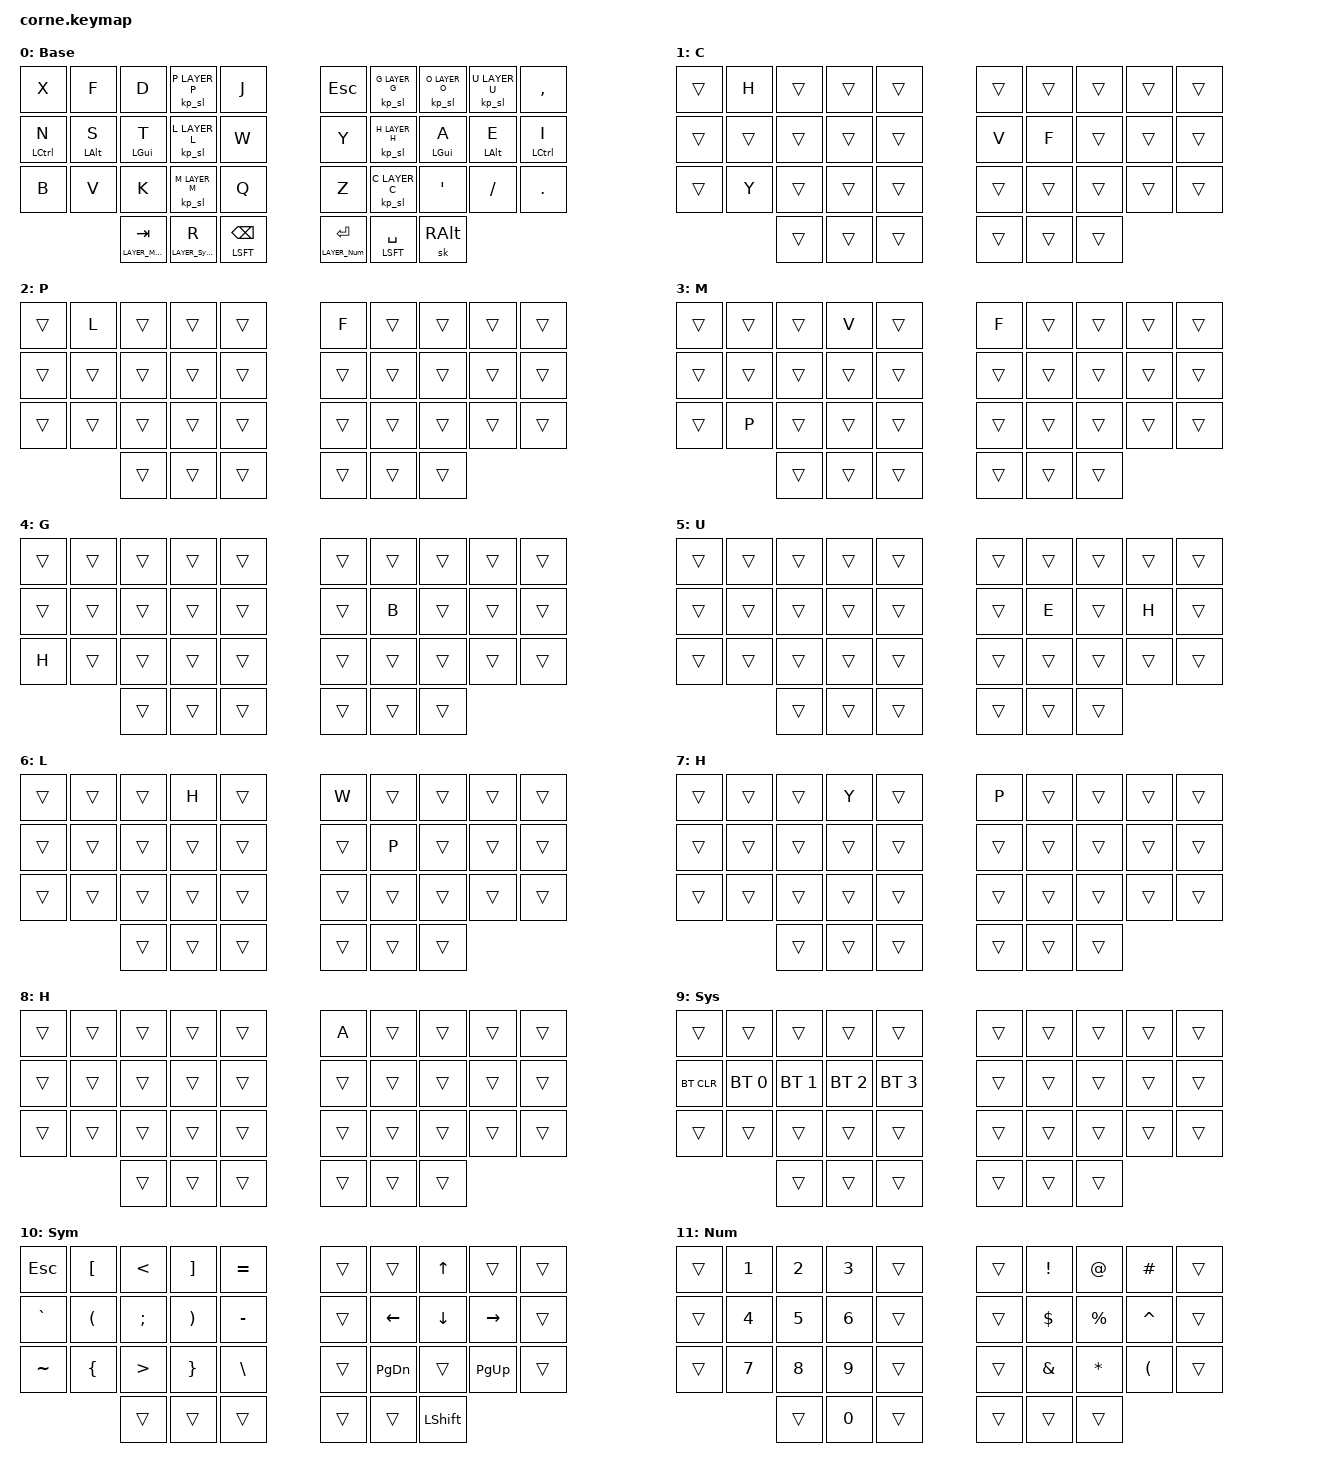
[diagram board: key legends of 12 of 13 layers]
/*
 * Copyright (c) 2020 The ZMK Contributors
 *
 * SPDX-License-Identifier: MIT
 */

#include <behaviors.dtsi>
#include <dt-bindings/zmk/keys.h>
#include <dt-bindings/zmk/bt.h>
#include <behaviors/mouse_keys.dtsi>
#include <dt-bindings/zmk/keys.h>
#include <dt-bindings/zmk/bt.h>
#include <dt-bindings/zmk/mouse.h> 

#define ZMK_MOUSE_DEFAULT_MOVE_VAL 2250
#define U_MOUSE_MOVE_EXPONENT 2
#define U_MOUSE_MOVE_TIME 650
#define U_MOUSE_MOVE_DELAY 0

#define LAYER_C 1
#define LAYER_P 2
#define LAYER_M 3
#define LAYER_G 4
#define LAYER_U 5
#define LAYER_L 6
#define LAYER_H 7
#define LAYER_O 8
#define LAYER_Magic 9
#define LAYER_Symbols 10
#define LAYER_Num 11
#define LAYER_Mouse 12

/ {
behaviors {
   hm: homerow_mods {
       compatible = "zmk,behavior-hold-tap";
       label = "HOMEROW_MODS";
       #binding-cells = <2>;
       tapping-term-ms = <200>;
       quick-tap-ms = <0>;
            flavor = "balanced";
            bindings = <&kp>, <&kp>;
    };
    as: auto_shift {
        compatible = "zmk,behavior-hold-tap";
        label = "AUTO_SHIFT";
        #binding-cells = <2>;
        tapping_term_ms = <250>;
        quick_tap_ms = <0>;
        flavor = "tap-preferred";
        bindings = <&kp>, <&kp>;
    };
    mm_bspc_del: mm_backspace_delete {
        compatible = "zmk,behavior-mod-morph";
        label = "MM_BACKSPACE_DELETE";
        #binding-cells = <0>;
        bindings = <&kp BACKSPACE>, <&kp DELETE>;
        mods = <(MOD_LSFT|MOD_RSFT)>;
    };

    kp_sl: kp_sl {
  label = "keypress and sticky layer";
  compatible = "zmk,behavior-macro-two-param";
  #binding-cells = <2>;
  bindings
    = <&macro_param_1to1>
    , <&macro_tap &kp MACRO_PLACEHOLDER>
    , <&macro_param_2to1>
    , <&macro_tap &sl MACRO_PLACEHOLDER>
    ;
};
};
};
/ {
        keymap {
                compatible = "zmk,keymap";

                default_layer {
                        display-name = "Base";
                        bindings = <
   &kp X &kp F &kp D &kp_sl P LAYER_P &kp J                              &kp ESC &kp_sl G LAYER_G  &kp_sl O LAYER_O     &kp_sl U LAYER_U   &kp COMMA
   &hm LCTRL N &hm LALT S &hm LGUI T &kp_sl L LAYER_L &kp W   &kp Y &kp_sl H LAYER_H  &hm LGUI A     &hm LALT E   &hm LCTRL I 
   &kp B &kp V &kp K &kp_sl M LAYER_M &kp Q                              &kp Z &kp_sl C LAYER_C  &kp SQT &kp FSLH &kp DOT 
               &lt LAYER_Mouse TAB &lt LAYER_Symbols R  &hm LSFT BSPC                             &lt LAYER_Num RET &hm LSFT SPACE &sk RALT
                        >;
                };

                layer_c {
                        display-name = "C";
                        bindings = <
   &trans &kp H &trans &trans &trans                              &trans &trans  &trans     &trans   &trans
   &trans &trans &trans &trans &trans                              &kp V &kp F  &trans     &trans   &trans
   &trans &kp Y &trans &trans &trans                              &trans &trans  &trans     &trans   &trans
                  &trans &trans &trans                              &trans &trans &trans
                        >;
                };

                layer_p {
                        display-name = "P";
                        bindings = <
   &trans &kp L &trans &trans &trans                              &kp F &trans  &trans     &trans   &trans
   &trans &trans &trans &trans &trans                              &trans &trans  &trans     &trans   &trans
   &trans &trans &trans &trans &trans                              &trans &trans  &trans     &trans   &trans
                  &trans &trans &trans                              &trans &trans &trans
                        >;
                };

                layer_m {
                        display-name = "M";
                        bindings = <
   &trans &trans &trans &kp V &trans                              &kp F &trans  &trans     &trans   &trans
   &trans &trans &trans &trans &trans                              &trans &trans  &trans     &trans   &trans
   &trans &kp P &trans &trans &trans                              &trans &trans  &trans     &trans   &trans
                  &trans &trans &trans                              &trans &trans &trans
                        >;
                };

                layer_g {
                        display-name = "G";
                        bindings = <
   &trans &trans &trans &trans &trans                              &trans &trans  &trans     &trans   &trans
   &trans &trans &trans &trans &trans                              &trans &kp B  &trans     &trans   &trans
   &kp H &trans &trans &trans &trans                              &trans &trans  &trans     &trans   &trans
                  &trans &trans &trans                              &trans &trans &trans
                        >;
                };

                layer_u {
                        display-name = "U";
                        bindings = <
   &trans &trans &trans &trans &trans                              &trans &trans  &trans     &trans   &trans
   &trans &trans &trans &trans &trans                              &trans &kp E  &trans     &kp H   &trans
   &trans &trans &trans &trans &trans                              &trans &trans  &trans     &trans   &trans
                  &trans &trans &trans                              &trans &trans &trans
                        >;
                };

                layer_l {
                        display-name = "L";
                        bindings = <
   &trans &trans &trans &kp H &trans                              &kp W &trans  &trans     &trans   &trans
   &trans &trans &trans &trans &trans                              &trans &kp P  &trans     &trans   &trans
   &trans &trans &trans &trans &trans                              &trans &trans  &trans     &trans   &trans
                  &trans &trans &trans                              &trans &trans &trans
                        >;
                };

                layer_h {
                        display-name = "H";
                        bindings = <
   &trans &trans &trans &kp Y &trans                              &kp P &trans  &trans     &trans   &trans
   &trans &trans &trans &trans &trans                              &trans &trans  &trans     &trans   &trans
   &trans &trans &trans &trans &trans                              &trans &trans  &trans     &trans   &trans
                  &trans &trans &trans                              &trans &trans &trans
                        >;
                };

                layer_o {
                        display-name = "H";
                        bindings = <
   &trans &trans &trans &trans &trans                              &kp A &trans  &trans     &trans   &trans
   &trans &trans &trans &trans &trans                              &trans &trans  &trans     &trans   &trans
   &trans &trans &trans &trans &trans                              &trans &trans  &trans     &trans   &trans
                  &trans &trans &trans                              &trans &trans &trans
                        >;
                };

                layer_sys {
                        display-name = "Sys";
                        bindings = <
   &trans &trans &trans &trans &trans                              &trans &trans  &trans     &trans   &trans
   &bt BT_CLR &bt BT_SEL 0 &bt BT_SEL 1 &bt BT_SEL 2 &bt BT_SEL 3  &trans &trans  &trans     &trans   &trans
   &trans &trans &trans &trans &trans                              &trans &trans  &trans     &trans   &trans
                  &trans &trans &trans                              &trans &trans &trans
                        >;
                };

                layer_sym {
                        display-name = "Sym";
                        bindings = <
   &kp ESC &kp LBKT &kp LT &kp RBKT &kp EQUAL                              &trans &trans  &kp UP     &trans   &trans
   &kp GRAVE &kp LPAR &kp SEMI &kp RPAR &kp MINUS                              &trans &kp LEFT  &kp DOWN     &kp RIGHT   &trans
   &kp TILDE &kp LBRC &kp GT &kp RBRC &kp BSLH                              &trans &kp PAGE_DOWN  &trans     &kp PAGE_UP   &trans
                  &trans &trans &trans                              &trans &trans &kp LSHFT
                        >;
                };

                layer_num {
                        display-name = "Num";
                        bindings = <
   &trans &kp N1 &kp N2 &kp N3 &trans                              &trans &kp EXCL  &kp AT     &kp HASH   &trans
   &trans &kp N4 &kp N5 &kp N6 &trans                              &trans &kp DLLR  &kp PRCNT     &kp CARET   &trans
   &trans &kp N7 &kp N8 &kp N9 &trans                              &trans &kp AMPS  &kp STAR     &kp LPAR   &trans
                  &trans &kp N0 &trans                              &trans &trans &trans
                        >;
                };

                layer_mouse {
                        display-name = "Mouse";
                        bindings = <
   &trans &trans &trans &trans &trans                              &trans &trans  &mmv MOVE_UP     &trans   &trans
   &trans &mkp LCLK &trans &mkp RCLK &trans                              &trans &mmv MOVE_LEFT  &mmv MOVE_DOWN     &mmv MOVE_RIGHT   &trans
   &trans &trans &trans &trans &trans                              &trans &kp PAGE_DOWN  &trans     &kp PAGE_UP   &trans
                  &trans &trans &trans                              &trans &trans &trans
                        >;
                };
        };
};
